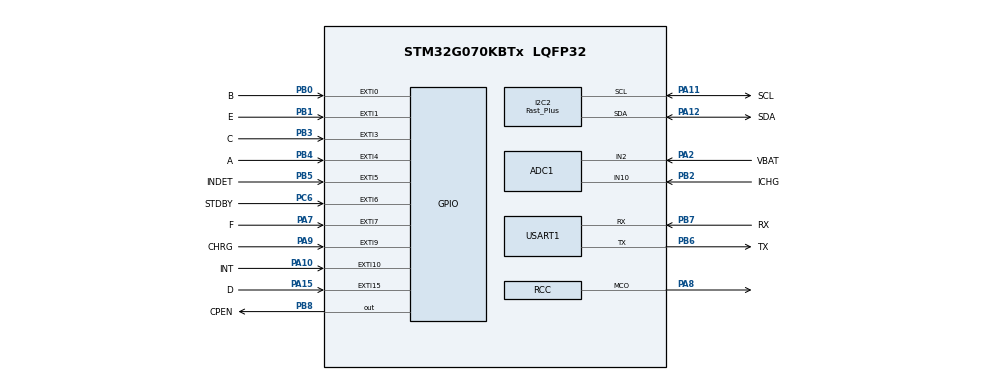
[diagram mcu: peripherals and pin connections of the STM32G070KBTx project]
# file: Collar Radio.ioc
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ADC1.ClockPrescaler=ADC_CLOCK_ASYNC_DIV8
ADC1.EOCSelection=ADC_EOC_SEQ_CONV
ADC1.NbrOfConversion=1
ADC1.NbrOfConversionFlag=0
ADC1.OversamplingMode=DISABLE
ADC1.SamplingTimeCommon1=ADC_SAMPLETIME_39CYCLES_5
ADC1.SelectedChannel=ADC_CHANNEL_2|ADC_CHANNEL_TEMPSENSOR|ADC_CHANNEL_VREFINT|ADC_CHANNEL_10
ADC1.Sequencer=NOT_FULLY_CONFIGURABLE
ADC1.TriggerFrequencyMode=ADC_TRIGGER_FREQ_HIGH
ADC1.master=1
Dma.ADC1.1.Direction=DMA_PERIPH_TO_MEMORY
Dma.ADC1.1.EventEnable=DISABLE
Dma.ADC1.1.Instance=DMA1_Channel5
Dma.ADC1.1.MemDataAlignment=DMA_MDATAALIGN_HALFWORD
Dma.ADC1.1.MemInc=DMA_MINC_ENABLE
Dma.ADC1.1.Mode=DMA_NORMAL
Dma.ADC1.1.PeriphDataAlignment=DMA_PDATAALIGN_HALFWORD
Dma.ADC1.1.PeriphInc=DMA_PINC_DISABLE
Dma.ADC1.1.Polarity=HAL_DMAMUX_REQ_GEN_RISING
Dma.ADC1.1.Priority=DMA_PRIORITY_LOW
Dma.ADC1.1.RequestNumber=1
Dma.ADC1.1.SignalID=NONE
Dma.ADC1.1.SyncEnable=DISABLE
Dma.ADC1.1.SyncPolarity=HAL_DMAMUX_SYNC_NO_EVENT
Dma.ADC1.1.SyncRequestNumber=1
Dma.ADC1.1.SyncSignalID=NONE
Dma.I2C2_RX.3.Direction=DMA_PERIPH_TO_MEMORY
Dma.I2C2_RX.3.EventEnable=DISABLE
Dma.I2C2_RX.3.Instance=DMA1_Channel3
Dma.I2C2_RX.3.MemDataAlignment=DMA_MDATAALIGN_BYTE
Dma.I2C2_RX.3.MemInc=DMA_MINC_ENABLE
Dma.I2C2_RX.3.Mode=DMA_NORMAL
Dma.I2C2_RX.3.PeriphDataAlignment=DMA_PDATAALIGN_BYTE
Dma.I2C2_RX.3.PeriphInc=DMA_PINC_DISABLE
Dma.I2C2_RX.3.Polarity=HAL_DMAMUX_REQ_GEN_RISING
Dma.I2C2_RX.3.Priority=DMA_PRIORITY_LOW
Dma.I2C2_RX.3.RequestNumber=1
Dma.I2C2_RX.3.SignalID=NONE
Dma.I2C2_RX.3.SyncEnable=DISABLE
Dma.I2C2_RX.3.SyncPolarity=HAL_DMAMUX_SYNC_NO_EVENT
Dma.I2C2_RX.3.SyncRequestNumber=1
Dma.I2C2_RX.3.SyncSignalID=NONE
Dma.I2C2_TX.2.Direction=DMA_MEMORY_TO_PERIPH
Dma.I2C2_TX.2.EventEnable=DISABLE
Dma.I2C2_TX.2.Instance=DMA1_Channel4
Dma.I2C2_TX.2.MemDataAlignment=DMA_MDATAALIGN_BYTE
Dma.I2C2_TX.2.MemInc=DMA_MINC_ENABLE
Dma.I2C2_TX.2.Mode=DMA_NORMAL
Dma.I2C2_TX.2.PeriphDataAlignment=DMA_PDATAALIGN_BYTE
Dma.I2C2_TX.2.PeriphInc=DMA_PINC_DISABLE
Dma.I2C2_TX.2.Polarity=HAL_DMAMUX_REQ_GEN_RISING
Dma.I2C2_TX.2.Priority=DMA_PRIORITY_LOW
Dma.I2C2_TX.2.RequestNumber=1
Dma.I2C2_TX.2.SignalID=NONE
Dma.I2C2_TX.2.SyncEnable=DISABLE
Dma.I2C2_TX.2.SyncPolarity=HAL_DMAMUX_SYNC_NO_EVENT
Dma.I2C2_TX.2.SyncRequestNumber=1
Dma.I2C2_TX.2.SyncSignalID=NONE
Dma.Request0=USART1_TX
Dma.Request1=ADC1
Dma.Request2=I2C2_TX
Dma.Request3=I2C2_RX
Dma.USART1_TX.0.Direction=DMA_MEMORY_TO_PERIPH
Dma.USART1_TX.0.EventEnable=DISABLE
Dma.USART1_TX.0.Instance=DMA1_Channel7
Dma.USART1_TX.0.MemDataAlignment=DMA_MDATAALIGN_BYTE
Dma.USART1_TX.0.MemInc=DMA_MINC_ENABLE
Dma.USART1_TX.0.Mode=DMA_NORMAL
Dma.USART1_TX.0.PeriphDataAlignment=DMA_PDATAALIGN_BYTE
Dma.USART1_TX.0.PeriphInc=DMA_PINC_DISABLE
Dma.USART1_TX.0.Polarity=HAL_DMAMUX_REQ_GEN_RISING
Dma.USART1_TX.0.Priority=DMA_PRIORITY_LOW
Dma.USART1_TX.0.RequestNumber=1
Dma.USART1_TX.0.SignalID=NONE
Dma.USART1_TX.0.SyncEnable=DISABLE
Dma.USART1_TX.0.SyncPolarity=HAL_DMAMUX_SYNC_NO_EVENT
Dma.USART1_TX.0.SyncRequestNumber=1
Dma.USART1_TX.0.SyncSignalID=NONE
FREERTOS.BinarySemaphores01=mutex_i2c_idle,Static,mutex_i2c_idleControlBlock,Available;mutex_i2c_busy,Static,mutex_i2c_busyControlBlock,Depleted;mutex_disp_idle,Static,mutex_disp_idleControlBlock,Available
FREERTOS.HEAP_NUMBER=1
FREERTOS.Queues01=Button_Queue,32,uint16_t,0,Static,Button_QueueBuffer,Button_QueueControlBlock;Notification_Queue,16,const char*,0,Static,NotificationQueueBuffer,NotificationQueueControlBlock
FREERTOS.Tasks01=SysShutdown,24,128,SysShutdown_Task,As weak,NULL,Static,SysShutdownBuffer,SysShutdownControlBlock;Menu,24,512,Menu_Task,As weak,NULL,Static,MenuBuffer,MenuControlBlock;ADC_Update,16,64,ADC_Task,As weak,NULL,Static,ADC_UpdateBuffer,ADC_UpdateControlBlock;PressureSensor,16,64,AirPressure_Task,As weak,NULL,Static,PressureSensorBuffer,PressureSensorControlBlock;ButtonTask,40,64,Button_Handle,As weak,NULL,Static,ButtonTaskBuffer,ButtonTaskControlBlock;Notification,24,128,Notification_Task,As weak,NULL,Static,NotificationBuffer,NotificationControlBlock;SC7A20,24,64,SC7A20_Task,As weak,NULL,Static,SC7A20Buffer,SC7A20ControlBlock
FREERTOS.configENABLE_FPU=0
FREERTOS.configMINIMAL_STACK_SIZE=64
FREERTOS.configTOTAL_HEAP_SIZE=512
FREERTOS.configUSE_IDLE_HOOK=1
I2C2.I2C_Fall_Time=50
I2C2.I2C_Speed_Mode=I2C_Fast_Plus
I2C2.Speed=820
I2C2.Timing=0x00900B2D
Mcu.Family=STM32G0
Mcu.Name=STM32G070KBTx
Mcu.Package=LQFP32
NVIC.ADC1_IRQn=true\:3\:0\:false\:false\:true\:true\:true\:true\:true
NVIC.DMA1_Ch4_7_DMAMUX1_OVR_IRQn=true\:3\:0\:false\:false\:true\:true\:false\:true\:true
NVIC.DMA1_Channel2_3_IRQn=true\:3\:0\:false\:false\:true\:true\:false\:true\:true
NVIC.EXTI0_1_IRQn=true\:3\:0\:true\:false\:true\:true\:true\:true\:true
NVIC.EXTI2_3_IRQn=true\:3\:0\:true\:false\:true\:true\:true\:true\:true
NVIC.EXTI4_15_IRQn=true\:3\:0\:true\:false\:true\:true\:true\:true\:true
NVIC.I2C2_IRQn=true\:3\:0\:false\:false\:true\:true\:true\:true\:true
NVIC.RTC_TAMP_IRQn=true\:3\:0\:false\:false\:true\:true\:true\:true\:true
NVIC.USART1_IRQn=true\:3\:0\:false\:false\:true\:true\:true\:true\:true
PA10.GPIO_Label=INT
PA10.GPIO_ModeDefaultEXTI=GPIO_MODE_IT_FALLING
PA10.GPIO_PuPd=GPIO_PULLUP
PA10.Signal=GPXTI10
PA11\ [PA9].GPIO_Label=SCL
PA11\ [PA9].GPIO_Pu=GPIO_PULLUP
PA11\ [PA9].GPIO_Speed=GPIO_SPEED_FREQ_HIGH
PA11\ [PA9].Mode=I2C
PA11\ [PA9].Signal=I2C2_SCL
PA12\ [PA10].GPIO_Label=SDA
PA12\ [PA10].GPIO_Pu=GPIO_PULLUP
PA12\ [PA10].GPIO_Speed=GPIO_SPEED_FREQ_HIGH
PA12\ [PA10].Mode=I2C
PA12\ [PA10].Signal=I2C2_SDA
PA13.Mode=Serial_Wire
PA13.Signal=SYS_SWDIO
PA14-BOOT0.Mode=Serial_Wire
PA14-BOOT0.Signal=SYS_SWCLK
PA15.GPIO_Label=D
PA15.GPIO_ModeDefaultEXTI=GPIO_MODE_IT_FALLING
PA15.GPIO_PuPd=GPIO_PULLUP
PA15.Signal=GPXTI15
PA2.GPIO_Label=VBAT
PA2.Mode=IN2
PA2.Signal=ADC1_IN2
PA7.GPIO_Label=F
PA7.GPIO_ModeDefaultEXTI=GPIO_MODE_IT_FALLING
PA7.GPIO_PuPd=GPIO_PULLUP
PA7.Signal=GPXTI7
PA8.GPIO_Speed=GPIO_SPEED_FREQ_LOW
PA8.Mode=Clock-out
PA8.Signal=RCC_MCO
PA9.GPIO_Label=CHRG
PA9.GPIO_ModeDefaultEXTI=GPIO_MODE_IT_FALLING
PA9.GPIO_PuPd=GPIO_PULLUP
PA9.Signal=GPXTI9
PB0.GPIO_Label=B
PB0.GPIO_ModeDefaultEXTI=GPIO_MODE_IT_FALLING
PB0.GPIO_PuPd=GPIO_PULLUP
PB0.Signal=GPXTI0
PB1.GPIO_Label=E
PB1.GPIO_ModeDefaultEXTI=GPIO_MODE_IT_FALLING
PB1.GPIO_PuPd=GPIO_PULLUP
PB1.Signal=GPXTI1
PB2.GPIO_Label=ICHG
PB2.Mode=IN10
PB2.Signal=ADC1_IN10
PB3.GPIO_Label=C
PB3.GPIO_ModeDefaultEXTI=GPIO_MODE_IT_FALLING
PB3.GPIO_PuPd=GPIO_PULLUP
PB3.Signal=GPXTI3
PB4.GPIO_Label=A
PB4.GPIO_ModeDefaultEXTI=GPIO_MODE_IT_FALLING
PB4.GPIO_PuPd=GPIO_PULLUP
PB4.Signal=GPXTI4
PB5.GPIO_Label=INDET
PB5.GPIO_ModeDefaultEXTI=GPIO_MODE_IT_RISING_FALLING
PB5.GPIO_PuPd=GPIO_PULLUP
PB5.Signal=GPXTI5
PB6.GPIO_Label=TX
PB6.GPIO_Speed=GPIO_SPEED_FREQ_MEDIUM
PB6.Mode=Asynchronous
PB6.Signal=USART1_TX
PB7.GPIO_Label=RX
PB7.GPIO_Speed=GPIO_SPEED_FREQ_MEDIUM
PB7.Mode=Asynchronous
PB7.Signal=USART1_RX
PB8.GPIO_Label=CPEN
PB8.PinState=GPIO_PIN_RESET
PB8.Signal=GPIO_Output
PC14-OSC32_IN\ (PC14).Mode=LSE-External-Oscillator
PC14-OSC32_IN\ (PC14).Signal=RCC_OSC32_IN
PC15-OSC32_OUT\ (PC15).Mode=LSE-External-Oscillator
PC15-OSC32_OUT\ (PC15).Signal=RCC_OSC32_OUT
PC6.GPIO_Label=STDBY
PC6.GPIO_ModeDefaultEXTI=GPIO_MODE_IT_FALLING
PC6.GPIO_PuPd=GPIO_PULLUP
PC6.Signal=GPXTI6
ProjectManager.HeapSize=0x200
ProjectManager.StackSize=0x800
ProjectManager.TargetToolchain=MDK-ARM V5.32
RCC.ADCCLockSelection=RCC_ADCCLKSOURCE_HSI
RCC.ADCFreq_Value=16000000
RCC.AHBFreq_Value=64000000
RCC.CortexFreq_Value=64000000
RCC.EXTERNAL_CLOCK_VALUE=48000
RCC.HCLKFreq_Value=64000000
RCC.HSE_VALUE=8000000
RCC.HSI_VALUE=16000000
RCC.LSE_Drive_Capability=RCC_LSEDRIVE_MEDIUMLOW
RCC.PLLP=RCC_PLLP_DIV4
RCC.RCC_MCO1Source=RCC_MCO1SOURCE_LSE
RCC.RTCClockSelection=RCC_RTCCLKSOURCE_LSE
RCC.SYSCLKFreq_VALUE=64000000
RCC.SYSCLKSource=RCC_SYSCLKSOURCE_PLLCLK
RCC.VCOOutputFreq_Value=128000000
RCC.VDD_VALUE=3.2
RTC.Format=RTC_FORMAT_BIN
RTC.WakeUpClock-WakeUp=RTC_WAKEUPCLOCK_CK_SPRE_16BITS
RTC.WakeUpCounter-WakeUp=299
USART1.VirtualMode-Asynchronous=VM_ASYNC
VP_ADC1_TempSens_Input.Mode=IN-TempSens
VP_ADC1_Vref_Input.Mode=IN-Vrefint
VP_FREERTOS_VS_CMSIS_V2.Mode=CMSIS_V2
VP_RTC_VS_RTC_Activate.Mode=RTC_Enabled
VP_RTC_VS_RTC_Calendar.Mode=RTC_Calendar
VP_RTC_VS_RTC_WakeUp_intern.Mode=WakeUp
board=custom

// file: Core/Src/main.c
/* USER CODE BEGIN Header */
/**
  ******************************************************************************
  * @file           : main.c
  * @brief          : Main program body
  ******************************************************************************
  * @attention
  *
  * Copyright (c) 2025 STMicroelectronics.
  * All rights reserved.
  *
  * This software is licensed under terms that can be found in the LICENSE file
  * in the root directory of this software component.
  * If no LICENSE file comes with this software, it is provided AS-IS.
  *
  ******************************************************************************
  */
/* USER CODE END Header */
#include "main.h"
#include "cmsis_os.h"
#include "adc.h"
#include "dma.h"
#include "i2c.h"
#include "rtc.h"
#include "usart.h"
#include "gpio.h"

/* USER CODE BEGIN Includes */
#include "oled.h"

#include "ui_conf.h"
/* USER CODE END Includes */

/* USER CODE BEGIN PV */
    u8g2_t u8g2;
/* USER CODE END PV */

void SystemClock_Config(void);
void MX_FREERTOS_Init(void);

int main(void)
{

  /* MCU Configuration--------------------------------------------------------*/

  /* Reset of all peripherals, Initializes the Flash interface and the Systick. */
  HAL_Init();

  /* Configure the system clock */
  SystemClock_Config();

  /* Initialize all configured peripherals */
  MX_GPIO_Init();
  MX_DMA_Init();
  MX_ADC1_Init();
  MX_I2C2_Init();
  MX_RTC_Init();
  MX_USART1_UART_Init();
  /* USER CODE BEGIN 2 */
    u8g2_Setup_ssd1312_i2c_128x64_noname_f(&u8g2, UI_DEFAULT_ROTATION, u8x8_byte_hw_i2c, u8x8_gpio_and_delay_hw);
    LL_PWR_EnableFlashPowerDownInStop();
    /*
    __HAL_RCC_PWR_CLK_ENABLE(); // 启用电源时钟
    __HAL_RCC_DBGMCU_CLK_ENABLE(); // 启用调试时钟
    HAL_DBGMCU_EnableDBGStopMode(); // 启用 STOP 模式下的调试功能
    */
  /* USER CODE END 2 */

  /* Init scheduler */
  osKernelInitialize();

  /* Call init function for freertos objects (in cmsis_os2.c) */
  MX_FREERTOS_Init();

  /* Start scheduler */
  osKernelStart();

  /* We should never get here as control is now taken by the scheduler */

  /* Infinite loop */
    while (1)
    {

    }
}

void SystemClock_Config(void)
{
  LL_FLASH_SetLatency(LL_FLASH_LATENCY_2);
  while(LL_FLASH_GetLatency() != LL_FLASH_LATENCY_2)
  {
  }

  /* HSI configuration and activation */
  LL_RCC_HSI_Enable();
  while(LL_RCC_HSI_IsReady() != 1)
  {
  }

  LL_PWR_EnableBkUpAccess();
  /* LSE configuration and activation */
  LL_RCC_LSE_SetDriveCapability(LL_RCC_LSEDRIVE_MEDIUMLOW);
  LL_RCC_LSE_Enable();
  while(LL_RCC_LSE_IsReady() != 1)
  {
  }

  /* Main PLL configuration and activation */
  LL_RCC_PLL_ConfigDomain_SYS(LL_RCC_PLLSOURCE_HSI, LL_RCC_PLLM_DIV_1, 8, LL_RCC_PLLR_DIV_2);
  LL_RCC_PLL_Enable();
  LL_RCC_PLL_EnableDomain_SYS();
  while(LL_RCC_PLL_IsReady() != 1)
  {
  }

  /* Set AHB prescaler*/
  LL_RCC_SetAHBPrescaler(LL_RCC_SYSCLK_DIV_1);

  /* Sysclk activation on the main PLL */
  LL_RCC_SetSysClkSource(LL_RCC_SYS_CLKSOURCE_PLL);
  while(LL_RCC_GetSysClkSource() != LL_RCC_SYS_CLKSOURCE_STATUS_PLL)
  {
  }

  /* Set APB1 prescaler*/
  LL_RCC_SetAPB1Prescaler(LL_RCC_APB1_DIV_1);
  /* Update CMSIS variable (which can be updated also through SystemCoreClockUpdate function) */
  LL_SetSystemCoreClock(64000000);

   /* Update the time base */
  if (HAL_InitTick (TICK_INT_PRIORITY) != HAL_OK)
  {
    Error_Handler();
  }
  LL_RCC_ConfigMCO(LL_RCC_MCO1SOURCE_LSE, LL_RCC_MCO1_DIV_1);
}

void Error_Handler(void)
{
  __disable_irq();
  while (1)
  {
  }
}

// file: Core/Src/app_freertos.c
/* USER CODE BEGIN Header */
/**
  ******************************************************************************
  * File Name          : app_freertos.c
  * Description        : Code for freertos applications
  ******************************************************************************
  * @attention
  *
  * Copyright (c) 2025 STMicroelectronics.
  * All rights reserved.
  *
  * This software is licensed under terms that can be found in the LICENSE file
  * in the root directory of this software component.
  * If no LICENSE file comes with this software, it is provided AS-IS.
  *
  ******************************************************************************
  */
/* USER CODE END Header */

#include "FreeRTOS.h"
#include "task.h"
#include "main.h"
#include "cmsis_os.h"

typedef StaticTask_t osStaticThreadDef_t;
typedef StaticQueue_t osStaticMessageQDef_t;
typedef StaticSemaphore_t osStaticSemaphoreDef_t;

/* Definitions for SysShutdown */
osThreadId_t SysShutdownHandle;
uint32_t SysShutdownBuffer[ 128 ];
osStaticThreadDef_t SysShutdownControlBlock;
const osThreadAttr_t SysShutdown_attributes = {
  .name = "SysShutdown",
  .stack_mem = &SysShutdownBuffer[0],
  .stack_size = sizeof(SysShutdownBuffer),
  .cb_mem = &SysShutdownControlBlock,
  .cb_size = sizeof(SysShutdownControlBlock),
  .priority = (osPriority_t) osPriorityNormal,
};
/* Definitions for Menu */
osThreadId_t MenuHandle;
uint32_t MenuBuffer[ 512 ];
osStaticThreadDef_t MenuControlBlock;
const osThreadAttr_t Menu_attributes = {
  .name = "Menu",
  .stack_mem = &MenuBuffer[0],
  .stack_size = sizeof(MenuBuffer),
  .cb_mem = &MenuControlBlock,
  .cb_size = sizeof(MenuControlBlock),
  .priority = (osPriority_t) osPriorityNormal,
};
/* Definitions for ADC_Update */
osThreadId_t ADC_UpdateHandle;
uint32_t ADC_UpdateBuffer[ 64 ];
osStaticThreadDef_t ADC_UpdateControlBlock;
const osThreadAttr_t ADC_Update_attributes = {
  .name = "ADC_Update",
  .stack_mem = &ADC_UpdateBuffer[0],
  .stack_size = sizeof(ADC_UpdateBuffer),
  .cb_mem = &ADC_UpdateControlBlock,
  .cb_size = sizeof(ADC_UpdateControlBlock),
  .priority = (osPriority_t) osPriorityBelowNormal,
};
/* Definitions for PressureSensor */
osThreadId_t PressureSensorHandle;
uint32_t PressureSensorBuffer[ 64 ];
osStaticThreadDef_t PressureSensorControlBlock;
const osThreadAttr_t PressureSensor_attributes = {
  .name = "PressureSensor",
  .stack_mem = &PressureSensorBuffer[0],
  .stack_size = sizeof(PressureSensorBuffer),
  .cb_mem = &PressureSensorControlBlock,
  .cb_size = sizeof(PressureSensorControlBlock),
  .priority = (osPriority_t) osPriorityBelowNormal,
};
/* Definitions for ButtonTask */
osThreadId_t ButtonTaskHandle;
uint32_t ButtonTaskBuffer[ 64 ];
osStaticThreadDef_t ButtonTaskControlBlock;
const osThreadAttr_t ButtonTask_attributes = {
  .name = "ButtonTask",
  .stack_mem = &ButtonTaskBuffer[0],
  .stack_size = sizeof(ButtonTaskBuffer),
  .cb_mem = &ButtonTaskControlBlock,
  .cb_size = sizeof(ButtonTaskControlBlock),
  .priority = (osPriority_t) osPriorityHigh,
};
/* Definitions for Notification */
osThreadId_t NotificationHandle;
uint32_t NotificationBuffer[ 128 ];
osStaticThreadDef_t NotificationControlBlock;
const osThreadAttr_t Notification_attributes = {
  .name = "Notification",
  .stack_mem = &NotificationBuffer[0],
  .stack_size = sizeof(NotificationBuffer),
  .cb_mem = &NotificationControlBlock,
  .cb_size = sizeof(NotificationControlBlock),
  .priority = (osPriority_t) osPriorityNormal,
};
/* Definitions for SC7A20 */
osThreadId_t SC7A20Handle;
uint32_t SC7A20Buffer[ 64 ];
osStaticThreadDef_t SC7A20ControlBlock;
const osThreadAttr_t SC7A20_attributes = {
  .name = "SC7A20",
  .stack_mem = &SC7A20Buffer[0],
  .stack_size = sizeof(SC7A20Buffer),
  .cb_mem = &SC7A20ControlBlock,
  .cb_size = sizeof(SC7A20ControlBlock),
  .priority = (osPriority_t) osPriorityNormal,
};
/* Definitions for Button_Queue */
osMessageQueueId_t Button_QueueHandle;
uint8_t Button_QueueBuffer[ 32 * sizeof( uint16_t ) ];
osStaticMessageQDef_t Button_QueueControlBlock;
const osMessageQueueAttr_t Button_Queue_attributes = {
  .name = "Button_Queue",
  .cb_mem = &Button_QueueControlBlock,
  .cb_size = sizeof(Button_QueueControlBlock),
  .mq_mem = &Button_QueueBuffer,
  .mq_size = sizeof(Button_QueueBuffer)
};
/* Definitions for Notification_Queue */
osMessageQueueId_t Notification_QueueHandle;
uint8_t NotificationQueueBuffer[ 16 * sizeof( const char* ) ];
osStaticMessageQDef_t NotificationQueueControlBlock;
const osMessageQueueAttr_t Notification_Queue_attributes = {
  .name = "Notification_Queue",
  .cb_mem = &NotificationQueueControlBlock,
  .cb_size = sizeof(NotificationQueueControlBlock),
  .mq_mem = &NotificationQueueBuffer,
  .mq_size = sizeof(NotificationQueueBuffer)
};
/* Definitions for mutex_i2c_idle */
osSemaphoreId_t mutex_i2c_idleHandle;
osStaticSemaphoreDef_t mutex_i2c_idleControlBlock;
const osSemaphoreAttr_t mutex_i2c_idle_attributes = {
  .name = "mutex_i2c_idle",
  .cb_mem = &mutex_i2c_idleControlBlock,
  .cb_size = sizeof(mutex_i2c_idleControlBlock),
};
/* Definitions for mutex_i2c_busy */
osSemaphoreId_t mutex_i2c_busyHandle;
osStaticSemaphoreDef_t mutex_i2c_busyControlBlock;
const osSemaphoreAttr_t mutex_i2c_busy_attributes = {
  .name = "mutex_i2c_busy",
  .cb_mem = &mutex_i2c_busyControlBlock,
  .cb_size = sizeof(mutex_i2c_busyControlBlock),
};
/* Definitions for mutex_disp_idle */
osSemaphoreId_t mutex_disp_idleHandle;
osStaticSemaphoreDef_t mutex_disp_idleControlBlock;
const osSemaphoreAttr_t mutex_disp_idle_attributes = {
  .name = "mutex_disp_idle",
  .cb_mem = &mutex_disp_idleControlBlock,
  .cb_size = sizeof(mutex_disp_idleControlBlock),
};

void SysShutdown_Task(void *argument);
void Menu_Task(void *argument);
void ADC_Task(void *argument);
void AirPressure_Task(void *argument);
void Button_Handle(void *argument);
void Notification_Task(void *argument);
void SC7A20_Task(void *argument);

void MX_FREERTOS_Init(void); /* (MISRA C 2004 rule 8.1) */

/* Hook prototypes */
void vApplicationIdleHook(void);

/* USER CODE BEGIN 2 */
//空闲任务钩子函数
void vApplicationIdleHook( void )
{
   /* vApplicationIdleHook() will only be called if configUSE_IDLE_HOOK is set
   to 1 in FreeRTOSConfig.h. It will be called on each iteration of the idle
   task. It is essential that code added to this hook function never attempts
   to block in any way (for example, call xQueueReceive() with a block time
   specified, or call vTaskDelay()). If the application makes use of the
   vTaskDelete() API function (as this demo application does) then it is also
   important that vApplicationIdleHook() is permitted to return to its calling
   function, because it is the responsibility of the idle task to clean up
   memory allocated by the kernel to any task that has since been deleted. */
    __WFI();//这里经过修改，加入了休眠指令，以提高电源效率
}
/* USER CODE END 2 */

void MX_FREERTOS_Init(void) {

  /* Create the semaphores(s) */
  /* creation of mutex_i2c_idle */
  mutex_i2c_idleHandle = osSemaphoreNew(1, 1, &mutex_i2c_idle_attributes);

  /* creation of mutex_i2c_busy */
  mutex_i2c_busyHandle = osSemaphoreNew(1, 0, &mutex_i2c_busy_attributes);

  /* creation of mutex_disp_idle */
  mutex_disp_idleHandle = osSemaphoreNew(1, 1, &mutex_disp_idle_attributes);

  /* Create the queue(s) */
  /* creation of Button_Queue */
  Button_QueueHandle = osMessageQueueNew (32, sizeof(uint16_t), &Button_Queue_attributes);

  /* creation of Notification_Queue */
  Notification_QueueHandle = osMessageQueueNew (16, sizeof(const char*), &Notification_Queue_attributes);

  /* Create the thread(s) */
  /* creation of SysShutdown */
  SysShutdownHandle = osThreadNew(SysShutdown_Task, NULL, &SysShutdown_attributes);

  /* creation of Menu */
  MenuHandle = osThreadNew(Menu_Task, NULL, &Menu_attributes);

  /* creation of ADC_Update */
  ADC_UpdateHandle = osThreadNew(ADC_Task, NULL, &ADC_Update_attributes);

  /* creation of PressureSensor */
  PressureSensorHandle = osThreadNew(AirPressure_Task, NULL, &PressureSensor_attributes);

  /* creation of ButtonTask */
  ButtonTaskHandle = osThreadNew(Button_Handle, NULL, &ButtonTask_attributes);

  /* creation of Notification */
  NotificationHandle = osThreadNew(Notification_Task, NULL, &Notification_attributes);

  /* creation of SC7A20 */
  SC7A20Handle = osThreadNew(SC7A20_Task, NULL, &SC7A20_attributes);

}

__weak void SysShutdown_Task(void *argument)
{
  for(;;)
  {
    osDelay(1);
  }
}

__weak void Menu_Task(void *argument)
{
  for(;;)
  {
    osDelay(1);
  }
}

__weak void ADC_Task(void *argument)
{
    for(;;)
    {
    }
}

__weak void AirPressure_Task(void *argument)
{
  for(;;)
  {
    osDelay(1);
  }
}

__weak void Button_Handle(void *argument)
{
  for(;;)
  {
    osDelay(1);
  }
}

__weak void Notification_Task(void *argument)
{
  for(;;)
  {
    osDelay(1);
  }
}

__weak void SC7A20_Task(void *argument)
{
  for(;;)
  {
    osDelay(1);
  }
}
